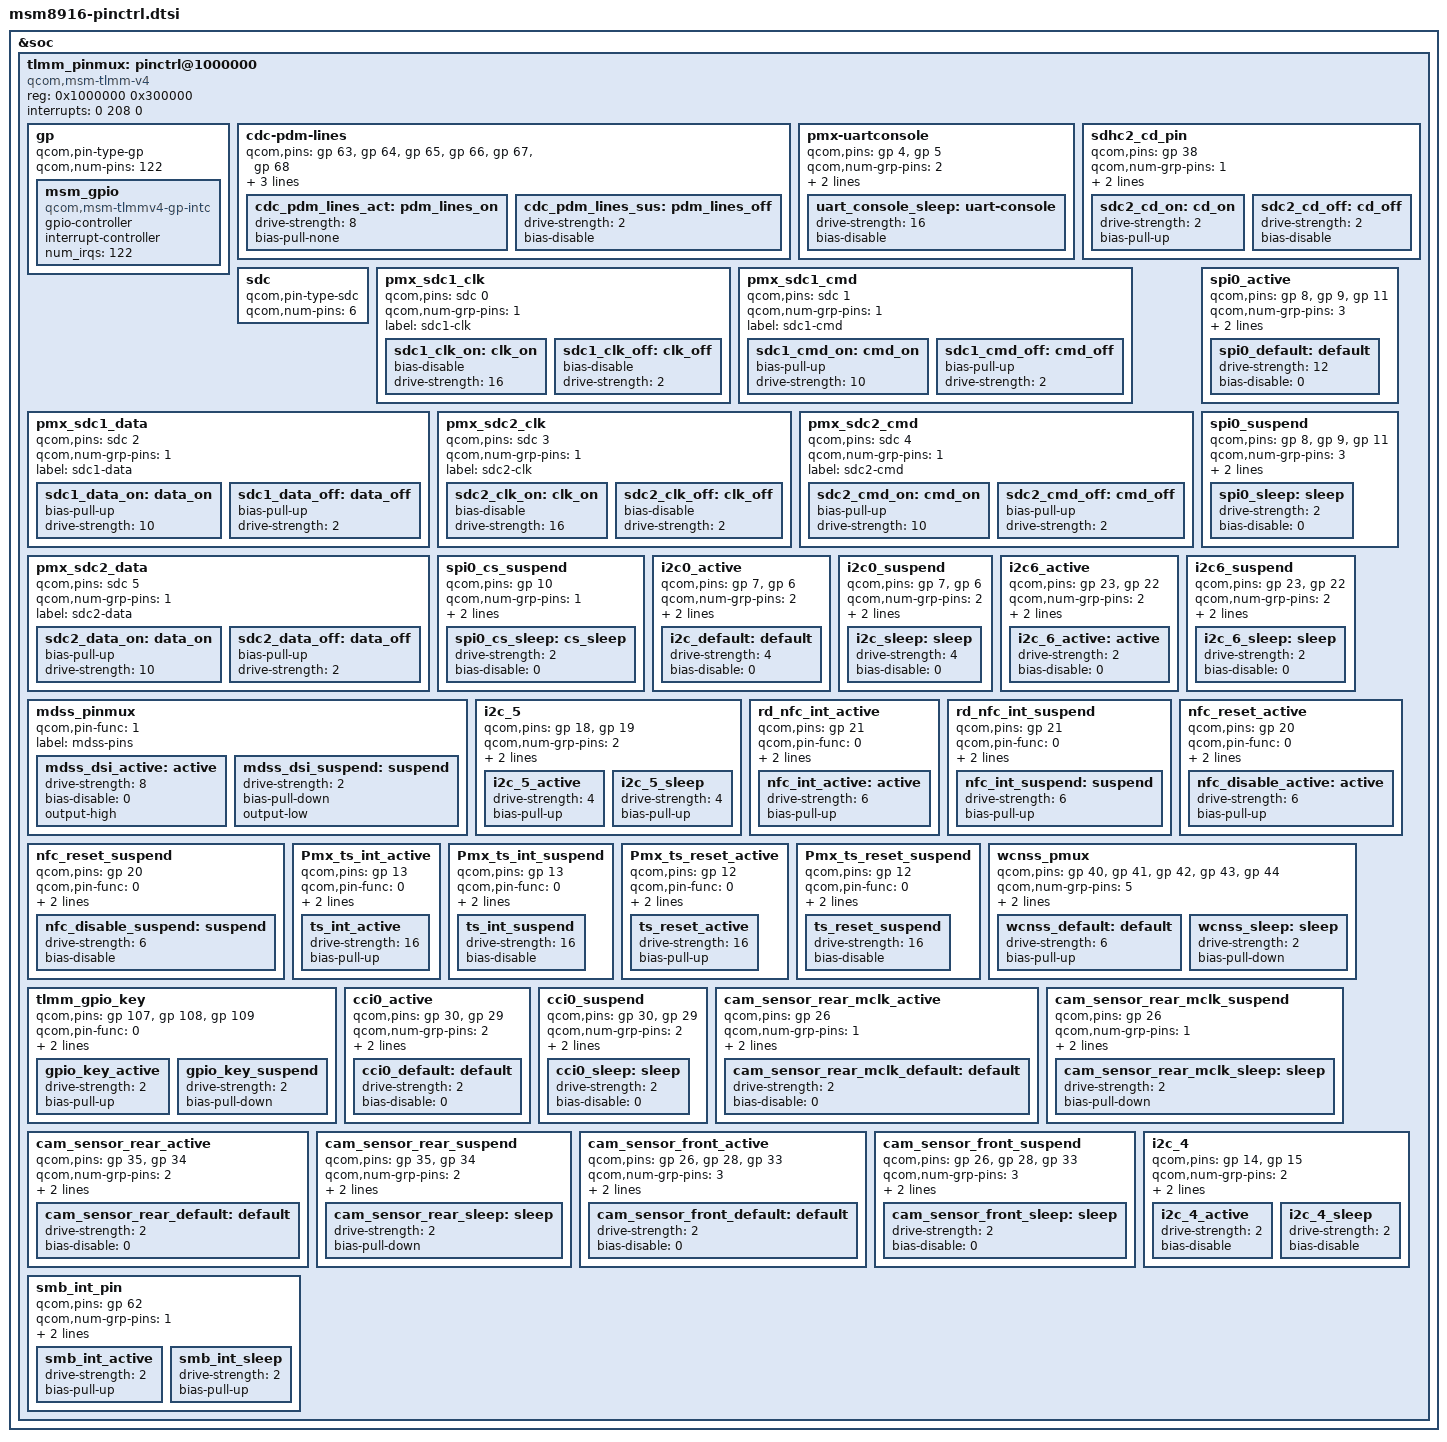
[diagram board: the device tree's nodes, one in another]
/* Copyright (c) 2013-2014, The Linux Foundation. All rights reserved.
 *
 * This program is free software; you can redistribute it and/or modify
 * it under the terms of the GNU General Public License version 2 and
 * only version 2 as published by the Free Software Foundation.
 *
 * This program is distributed in the hope that it will be useful,
 * but WITHOUT ANY WARRANTY; without even the implied warranty of
 * MERCHANTABILITY or FITNESS FOR A PARTICULAR PURPOSE.  See the
 * GNU General Public License for more details.
 */

&soc {
	tlmm_pinmux: pinctrl@1000000 {
		compatible = "qcom,msm-tlmm-v4";
		reg = <0x1000000 0x300000>;
		interrupts = <0 208 0>;

		/*General purpose pins*/
		gp: gp {
			qcom,pin-type-gp;
			qcom,num-pins = <122>;
			#qcom,pin-cells = <1>;
			msm_gpio: msm_gpio {
				compatible = "qcom,msm-tlmmv4-gp-intc";
				gpio-controller;
				#gpio-cells = <2>;
				interrupt-controller;
				#interrupt-cells = <2>;
				num_irqs = <122>;
			};
		};
		cdc-pdm-lines {
			qcom,pins = <&gp 63>, <&gp 64>, <&gp 65>,
					<&gp 66>, <&gp 67>, <&gp 68>;
			qcom,num-grp-pins = <6>;
			qcom,pin-func = <1>;
			label = "cdc-pdm-lines";
			cdc_pdm_lines_act: pdm_lines_on {
				drive-strength = <8>;
				bias-pull-none;
			};
			cdc_pdm_lines_sus: pdm_lines_off {
				drive-strength = <2>;
				bias-disable;
			};
		};
		pmx-uartconsole {
			qcom,pins = <&gp 4>, <&gp 5>;
			qcom,num-grp-pins = <2>;
			qcom,pin-func = <2>;
			label = "uart-console";

		uart_console_sleep: uart-console {
				drive-strength = <16>;
				bias-disable;
			};
		};

		sdhc2_cd_pin {
			qcom,pins = <&gp 38>;
			qcom,num-grp-pins = <1>;
			qcom,pin-func = <0>;
			label = "cd-gpio";
			sdc2_cd_on: cd_on {
				drive-strength = <2>;
				bias-pull-up;
			};
			sdc2_cd_off: cd_off {
				drive-strength = <2>;
				bias-disable;
			};
		};

		/* SDC pin type */
		sdc: sdc {
			qcom,pin-type-sdc;
			/* 0-2 for sdc1 3-5 for sdc2 */
			qcom,num-pins = <6>;
			/* Order of pins */
			/* CLK -> 0, CMD -> 1, DATA -> 2 */
			#qcom,pin-cells = <1>;
		};

		pmx_sdc1_clk {
			qcom,pins = <&sdc 0>;
			qcom,num-grp-pins = <1>;
			label = "sdc1-clk";
			sdc1_clk_on: clk_on {
				bias-disable; /* NO pull */
				drive-strength = <16>; /* 16 MA */
			};
			sdc1_clk_off: clk_off {
				bias-disable; /* NO pull */
				drive-strength = <2>; /* 2 MA */
			};
		};

		pmx_sdc1_cmd {
			qcom,pins = <&sdc 1>;
			qcom,num-grp-pins = <1>;
			label = "sdc1-cmd";
			sdc1_cmd_on: cmd_on {
				bias-pull-up; /* pull up */
				drive-strength = <10>; /* 10 MA */
			};
			sdc1_cmd_off: cmd_off {
				bias-pull-up; /* pull up */
				drive-strength = <2>; /* 2 MA */
			};
		};

		pmx_sdc1_data {
			qcom,pins = <&sdc 2>;
			qcom,num-grp-pins = <1>;
			label = "sdc1-data";
			sdc1_data_on: data_on {
				bias-pull-up; /* pull up */
				drive-strength = <10>; /* 10 MA */
			};
			sdc1_data_off: data_off {
				bias-pull-up; /* pull up */
				drive-strength = <2>; /* 2 MA */
			};
		};

		pmx_sdc2_clk {
			qcom,pins = <&sdc 3>;
			qcom,num-grp-pins = <1>;
			label = "sdc2-clk";
			sdc2_clk_on: clk_on {
				bias-disable; /* NO pull */
				drive-strength = <16>; /* 16 MA */
			};
			sdc2_clk_off: clk_off {
				bias-disable; /* NO pull */
				drive-strength = <2>; /* 2 MA */
			};
		};

		pmx_sdc2_cmd {
			qcom,pins = <&sdc 4>;
			qcom,num-grp-pins = <1>;
			label = "sdc2-cmd";
			sdc2_cmd_on: cmd_on {
				bias-pull-up; /* pull up */
				drive-strength = <10>; /* 10 MA */
			};
			sdc2_cmd_off: cmd_off {
				bias-pull-up; /* pull up */
				drive-strength = <2>; /* 2 MA */
			};
		};

		pmx_sdc2_data {
			qcom,pins = <&sdc 5>;
			qcom,num-grp-pins = <1>;
			label = "sdc2-data";
			sdc2_data_on: data_on {
				bias-pull-up; /* pull up */
				drive-strength = <10>; /* 10 MA */
			};
			sdc2_data_off: data_off {
				bias-pull-up; /* pull up */
				drive-strength = <2>; /* 2 MA */
			};
		};

		spi0_active {
			/* MOSI, MISO, CLK */
			qcom,pins = <&gp 8>, <&gp 9>, <&gp 11>;
			qcom,num-grp-pins = <3>;
			qcom,pin-func = <1>;
			label = "spi0-active";
			/* active state */
			spi0_default: default {
				drive-strength = <12>; /* 12 MA */
				bias-disable = <0>; /* No PULL */
			};
		};

		spi0_suspend {
			/* MOSI, MISO, CLK */
			qcom,pins = <&gp 8>, <&gp 9>, <&gp 11>;
			qcom,num-grp-pins = <3>;
			qcom,pin-func = <0>;
			label = "spi0-suspend";
			/* suspended state */
			spi0_sleep: sleep {
				drive-strength = <2>; /* 2 MA */
				bias-disable = <0>; /* No PULL */
			};
		};

		spi0_cs_suspend {
			/* CS */
			qcom,pins = <&gp 10>;
			qcom,num-grp-pins = <1>;
			qcom,pin-func = <0>;
			label = "spi0-cs-suspend";
			spi0_cs_sleep: cs_sleep {
				drive-strength = <2>;
				bias-disable = <0>;
			};
		};

		i2c0_active {
			/* CLK, DATA */
			qcom,pins = <&gp 7>, <&gp 6>;
			qcom,num-grp-pins = <2>;
			qcom,pin-func = <3>;
			label = "i2c0-active";
			/* active state */
			i2c_default: default {
				drive-strength = <4>; /* 2 MA */
				bias-disable = <0>; /* No PULL */
			};
		};

		i2c0_suspend {
			/* CLK, DATA */
			qcom,pins = <&gp 7>, <&gp 6>;
			qcom,num-grp-pins = <2>;
			qcom,pin-func = <0>;
			label = "i2c0-suspend";
			/*suspended state */
			i2c_sleep: sleep {
				drive-strength = <4>; /* 2 MA */
				bias-disable = <0>; /* No PULL */
			};
		};

		i2c6_active {
			/* CLK, DATA */
			qcom,pins = <&gp 23>, <&gp 22>;
			qcom,num-grp-pins = <2>;
			qcom,pin-func = <2>;
			label = "i2c6-active";
			/* active state */
			i2c_6_active: active {
				drive-strength = <2>; /* 2 MA */
				bias-disable = <0>; /* No PULL */
			};
		};

		i2c6_suspend {
			/* CLK, DATA */
			qcom,pins = <&gp 23>, <&gp 22>;
			qcom,num-grp-pins = <2>;
			qcom,pin-func = <0>;
			label = "i2c6-suspend";
			/*suspended state */
			i2c_6_sleep: sleep {
				drive-strength = <2>; /* 2 MA */
				bias-disable = <0>; /* No PULL */
			};
		};

		mdss_pinmux: mdss_pinmux {
			qcom,pin-func = <1>;
			label = "mdss-pins";
                        /* Can install other active-suspend
                         * pin configs for hdmi, edp etc.. */
			mdss_dsi_active: active {
				drive-strength = <8>; /* 8 mA */
				bias-disable = <0>; /* no pull */
				output-high;
			};

			mdss_dsi_suspend: suspend {
				drive-strength = <2>; /* 2 mA */
				bias-pull-down; /* pull down */
				output-low;
			};
		};

		i2c_5 {
			qcom,pins = <&gp 18>, <&gp 19>;
			qcom,num-grp-pins = <2>;
			qcom,pin-func = <2>;
			label = "i2c_5";

			i2c_5_active: i2c_5_active {
				drive-strength = <4>;
				bias-pull-up;
			};

			i2c_5_sleep: i2c_5_sleep {
				drive-strength = <4>;
				bias-pull-up;
			};
		};

		/* add pingrp for nfc */
		rd_nfc_int_active {
			qcom,pins = <&gp 21>;
			qcom,pin-func = <0>;
			qcom,num-grp-pins = <1>;
			label = "nfc_int_active";

			nfc_int_active: active {
				drive-strength = <6>;
				bias-pull-up;
			};
		};

		rd_nfc_int_suspend {
			qcom,pins = <&gp 21>;
			qcom,pin-func = <0>;
			qcom,num-grp-pins = <1>;
			label = "nfc_int_suspend";

			nfc_int_suspend: suspend {
				drive-strength = <6>;
				bias-pull-up;
			};
		};

		nfc_reset_active {
			qcom,pins = <&gp 20>;
			qcom,pin-func = <0>;
			qcom,num-grp-pins = <1>;
			label = "nfc_disable_active";

			nfc_disable_active: active {
				drive-strength = <6>;
				bias-pull-up;
			};
		};

		nfc_reset_suspend {
			qcom,pins = <&gp 20>;
			qcom,pin-func = <0>;
			qcom,num-grp-pins = <1>;
			label = "nfc_disable_suspend";

			nfc_disable_suspend: suspend {
				drive-strength = <6>;
				bias-disable;
			};
		};

		/* add pingrp for touchscreen */
		Pmx_ts_int_active {
			qcom,pins = <&gp 13>;
			qcom,pin-func = <0>;
			qcom,num-grp-pins = <1>;
			label = "pmx_ts_int_active";

			ts_int_active: ts_int_active {
				drive-strength = <16>;
				bias-pull-up;
			};
		};

		Pmx_ts_int_suspend {
			qcom,pins = <&gp 13>;
			qcom,pin-func = <0>;
			qcom,num-grp-pins = <1>;
			label = "pmx_ts_int_suspend";

			ts_int_suspend: ts_int_suspend {
				drive-strength = <16>;
				bias-disable;
			};
		};

		Pmx_ts_reset_active {
			qcom,pins = <&gp 12>;
			qcom,pin-func = <0>;
			qcom,num-grp-pins = <1>;
			label = "pmx_ts_reset_active";

			ts_reset_active: ts_reset_active {
				drive-strength = <16>;
				bias-pull-up;
			};
		};

		Pmx_ts_reset_suspend {
			qcom,pins = <&gp 12>;
			qcom,pin-func = <0>;
			qcom,num-grp-pins = <1>;
			label = "pmx_ts_reset_suspend";

			ts_reset_suspend: ts_reset_suspend {
				drive-strength = <16>;
				bias-disable;
			};
		};

		wcnss_pmux: wcnss_pmux {
			/* Uses general purpose pins */
			qcom,pins = <&gp 40>, <&gp 41>,
				    <&gp 42>, <&gp 43>,
				    <&gp 44>;
			qcom,num-grp-pins = <5>;
			qcom,pin-func = <1>;
			label = "wcnss_pins";
			/* Active configuration of bus pins */
			wcnss_default: default {
			        drive-strength = <6>; /* 6 MA */
			        bias-pull-up; /* PULL UP */
			};
			wcnss_sleep: sleep {
			        drive-strength = <2>; /* 2 MA */
			        bias-pull-down; /* PULL Down */
			};
		};

		tlmm_gpio_key {
			qcom,pins = <&gp 107>, <&gp 108>, <&gp 109>;
			qcom,pin-func = <0>;
			qcom,num-grp-pins = <3>;
			label = "tlmm_gpio_key";
			gpio_key_active: gpio_key_active {
				drive-strength = <2>;
				bias-pull-up;
			};
			gpio_key_suspend: gpio_key_suspend {
				drive-strength = <2>;
				bias-pull-down;
			};
		};

		cci0_active {
			/* CLK, DATA */
			qcom,pins = <&gp 30>, <&gp 29>;
			qcom,num-grp-pins = <2>;
			qcom,pin-func = <1>;
			label = "cci0-active";
			/* active state */
			cci0_default: default {
				drive-strength = <2>; /* 2 MA */
				bias-disable = <0>; /* No PULL */
			};
		};

		cci0_suspend {
			/* CLK, DATA */
			qcom,pins = <&gp 30>, <&gp 29>;
			qcom,num-grp-pins = <2>;
			qcom,pin-func = <1>;
			label = "cci0-suspend";
			/*suspended state */
			cci0_sleep: sleep {
				drive-strength = <2>; /* 2 MA */
				bias-disable = <0>; /* No PULL */
			};
		};

		cam_sensor_rear_mclk_active {
			/* MCLK */
			qcom,pins = <&gp 26>;
			qcom,num-grp-pins = <1>;
			qcom,pin-func = <1>;
			label = "cam-sensor-rear-mclk-active";
			/* active state */
			cam_sensor_rear_mclk_default: default {
				drive-strength = <2>; /* 2 MA */
				bias-disable = <0>; /* No PULL */
			};
		};

		cam_sensor_rear_mclk_suspend {
			/* MCLK */
			qcom,pins = <&gp 26>;
			qcom,num-grp-pins = <1>;
			qcom,pin-func = <1>;
			label = "cam-sensor-rear-mclk-suspend";
			/*suspended state */
			cam_sensor_rear_mclk_sleep: sleep {
				drive-strength = <2>; /* 2 MA */
				bias-pull-down; /* PULL DOWN */
			};
		};

		cam_sensor_rear_active {
			/* RESET, STANDBY */
			qcom,pins =  <&gp 35>, <&gp 34>;
			qcom,num-grp-pins = <2>;
			qcom,pin-func = <0>;
			label = "cam-sensor-rear-active";
			/* active state */
			cam_sensor_rear_default: default {
				drive-strength = <2>; /* 2 MA */
				bias-disable = <0>; /* No PULL */
			};
		};

		cam_sensor_rear_suspend {
			/* RESET, STANDBY */
			qcom,pins = <&gp 35>, <&gp 34>;
			qcom,num-grp-pins = <2>;
			qcom,pin-func = <0>;
			label = "cam-sensor-rear-suspend";
			/*suspended state */
			cam_sensor_rear_sleep: sleep {
				drive-strength = <2>; /* 2 MA */
				bias-pull-down; /* PULL DOWN */
			};
		};

		cam_sensor_front_active {
			/* MCLK, RESET, STANDBY */
			qcom,pins = <&gp 26>, <&gp 28>, <&gp 33>;
			qcom,num-grp-pins = <3>;
			qcom,pin-func = <1>;
			label = "cam_sensor_front_active";
			/* active state */
			cam_sensor_front_default: default {
				drive-strength = <2>; /* 2 MA */
				bias-disable = <0>; /* No PULL */
			};
		};

		cam_sensor_front_suspend {
			/* MCLK, RESET, STANDBY */
			qcom,pins = <&gp 26>, <&gp 28>, <&gp 33>;
			qcom,num-grp-pins = <3>;
			qcom,pin-func = <0>;
			label = "cam_sensor_front_suspend";
			/*suspended state */
			cam_sensor_front_sleep: sleep {
				drive-strength = <2>; /* 2 MA */
				bias-disable = <0>; /* No PULL */
			};
		};

		i2c_4 {
			qcom,pins = <&gp 14>, <&gp 15>;
			qcom,num-grp-pins = <2>;
			qcom,pin-func = <2>;
			label = "i2c_4";
			/* active state */
			i2c_4_active: i2c_4_active {
				drive-strength = <2>;	/* 2 MA */
				bias-disable;		/* No PULL */
			};
			/*suspended state */
			i2c_4_sleep: i2c_4_sleep {
				drive-strength = <2>;	/* 2 MA */
				bias-disable;		/* No PULL */
			};
		};

		smb_int_pin {
			qcom,pins = <&gp 62>;
			qcom,num-grp-pins = <1>;
			qcom,pin-func = <0>;
			label = "smb1360_int_gpio";
			smb_int_active: smb_int_active {
				drive-strength = <2>;	/* 2 MA */
				bias-pull-up;		/* PULL UP*/
			};
			smb_int_sleep: smb_int_sleep {
				drive-strength = <2>;	/* 2 MA */
				bias-pull-up;		/* PULL UP */
			};
		};
	};
};
